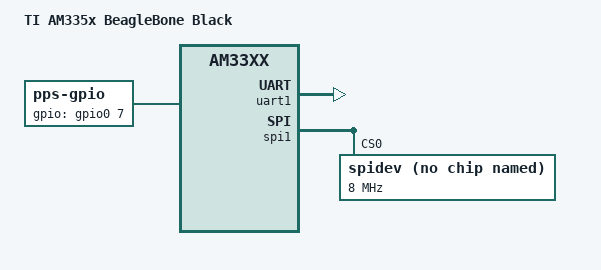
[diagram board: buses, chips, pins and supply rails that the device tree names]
/*
 * Copyright (C) 2012 Texas Instruments Incorporated - http://www.ti.com/
 *
 * This program is free software; you can redistribute it and/or modify
 * it under the terms of the GNU General Public License version 2 as
 * published by the Free Software Foundation.
 */
/dts-v1/;

#include "am33xx.dtsi"
#include "am335x-bone-common.dtsi"
#include "am335x-boneblack-common.dtsi"

/ {
	model = "TI AM335x BeagleBone Black";
	compatible = "ti,am335x-bone-black", "ti,am335x-bone", "ti,am33xx";
	
	pps {
		pinctrl-names = "default";
		pinctrl-0 = <&gps_pins>;
		compatible = "pps-gpio";
		gpios = <&gpio0 7 0>;
	};
};

&cpu0_opp_table {
	/*
	 * All PG 2.0 silicon may not support 1GHz but some of the early
	 * BeagleBone Blacks have PG 2.0 silicon which is guaranteed
	 * to support 1GHz OPP so enable it for PG 2.0 on this board.
	 */
	oppnitro-1000000000 {
		opp-supported-hw = <0x06 0x0100>;
	};
};

&am33xx_pinmux {
	uart1_pins: pinmux_uart1_pins {
		pinctrl-single,pins = <
			AM33XX_IOPAD(0x980, PIN_INPUT_PULLUP | MUX_MODE0)       /* uart1_rxd.uart1_rxd */
			AM33XX_IOPAD(0x984, PIN_OUTPUT_PULLDOWN | MUX_MODE0)    /* uart1_txd.uart1_txd */
		>;
	};

	spi1_pins: pinmux_spi1_pins {
		pinctrl-single,pins = <
			AM33XX_IOPAD(0x99c, PIN_OUTPUT_PULLUP | MUX_MODE3)	/* cs */
			AM33XX_IOPAD(0x994, PIN_INPUT_PULLUP | MUX_MODE3)	/* miso */
			AM33XX_IOPAD(0x998, PIN_OUTPUT_PULLUP | MUX_MODE3)	/* mosi */
			AM33XX_IOPAD(0x990, PIN_INPUT_PULLUP | MUX_MODE3)	/* sclk */
		>;
	};

	gps_pins: pinmux_gps_pins {
		pinctrl-single,pins = <
			AM33XX_IOPAD(0x9b4, PIN_OUTPUT_PULLUP | MUX_MODE7)       /* gpio20, en */
			AM33XX_IOPAD(0x964, PIN_INPUT_PULLDOWN | MUX_MODE7)    /* gpio7, pps */
			AM33XX_IOPAD(0x9a8, PIN_INPUT | MUX_MODE7)       /* gpio117, disable */
			AM33XX_IOPAD(0x9a0, PIN_INPUT | MUX_MODE7)    /* gpio114, disable */
		>;
	};
};

&uart1 {
	pinctrl-names = "default";
	pinctrl-0 = <&uart1_pins>;

        status = "okay";
};

&spi1 {
	pinctrl-names = "default";
	pinctrl-0 = <&spi1_pins>;
	status = "okay";
	spidev@0 {
		compatible = "spidev";
		spi-max-frequency = <8000000>;
		reg = <0>;
	};
};

&mcasp0 {
	status = "disabled";
};
